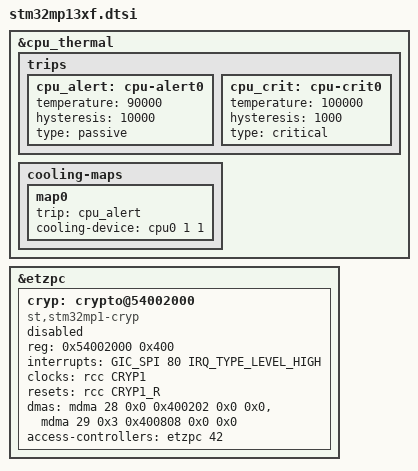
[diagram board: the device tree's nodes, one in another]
// SPDX-License-Identifier: (GPL-2.0+ OR BSD-3-Clause)
/*
 * Copyright (C) STMicroelectronics 2021 - All Rights Reserved
 * Author: Alexandre Torgue <alexandre.torgue@foss.st.com> for STMicroelectronics.
 */

&cpu_thermal {
	trips {
		cpu_alert: cpu-alert0 {
			temperature = <90000>;
			hysteresis = <10000>;
			type = "passive";
		};

		cpu_crit: cpu-crit0 {
			temperature = <100000>;
			hysteresis = <1000>;
			type = "critical";
		};
	};

	cooling-maps {
		map0 {
			trip = <&cpu_alert>;
			cooling-device = <&cpu0 1 1>;
		};
	};
};

&etzpc {
	cryp: crypto@54002000 {
		compatible = "st,stm32mp1-cryp";
		reg = <0x54002000 0x400>;
		interrupts = <GIC_SPI 80 IRQ_TYPE_LEVEL_HIGH>;
		clocks = <&rcc CRYP1>;
		resets = <&rcc CRYP1_R>;
		dmas = <&mdma 28 0x0 0x400202 0x0 0x0>,
		       <&mdma 29 0x3 0x400808 0x0 0x0>;
		dma-names = "mem2cryp", "cryp2mem";
		access-controllers = <&etzpc 42>;
		status = "disabled";
	};
};
